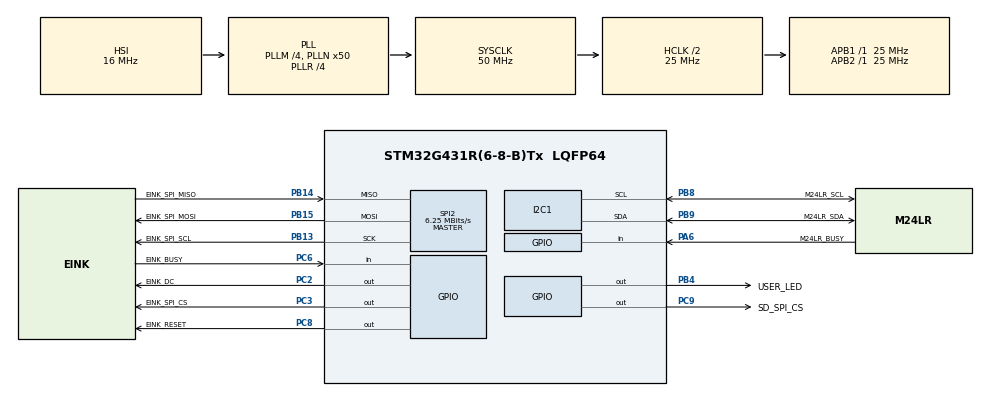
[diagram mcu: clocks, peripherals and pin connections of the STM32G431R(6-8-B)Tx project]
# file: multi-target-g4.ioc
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I2C1.Speed=50
I2C1.Timing=0x0080EBFC
Mcu.Family=STM32G4
Mcu.Name=STM32G431R(6-8-B)Tx
Mcu.Package=LQFP64
NVIC.PriorityGroup=NVIC_PRIORITYGROUP_4
PA13.GPIO_Label=T_SWDIO
PA13.Signal=SYS_JTMS-SWDIO
PA14.GPIO_Label=T_SWCLK
PA14.Signal=SYS_JTCK-SWCLK
PA6.GPIO_Label=M24LR_BUSY
PA6.Signal=GPIO_Input
PB13.GPIO_Label=EINK_SPI_SCL
PB13.Mode=Full_Duplex_Master
PB13.Signal=SPI2_SCK
PB14.GPIO_Label=EINK_SPI_MISO
PB14.Mode=Full_Duplex_Master
PB14.Signal=SPI2_MISO
PB15.GPIO_Label=EINK_SPI_MOSI
PB15.Mode=Full_Duplex_Master
PB15.Signal=SPI2_MOSI
PB3.GPIO_Label=T_SWO
PB3.Signal=SYS_JTDO-SWO
PB4.GPIO_Label=USER_LED
PB4.Signal=GPIO_Output
PB8-BOOT0.GPIO_Label=M24LR_SCL
PB8-BOOT0.Mode=I2C
PB8-BOOT0.Signal=I2C1_SCL
PB9.GPIO_Label=M24LR_SDA
PB9.Mode=I2C
PB9.Signal=I2C1_SDA
PC14-OSC32_IN.GPIO_Label=RCC_OSC32_OUT
PC14-OSC32_IN.Signal=RCC_OSC32_IN
PC15-OSC32_OUT.GPIO_Label=RCC_OSC32_OUT
PC15-OSC32_OUT.Signal=RCC_OSC32_OUT
PC2.GPIO_Label=EINK_DC
PC2.Signal=GPIO_Output
PC3.GPIO_Label=EINK_SPI_CS
PC3.Signal=GPIO_Output
PC6.GPIO_Label=EINK_BUSY
PC6.Signal=GPIO_Input
PC8.GPIO_Label=EINK_RESET
PC8.Signal=GPIO_Output
PC9.GPIO_Label=SD_SPI_CS
PC9.Signal=GPIO_Output
PF0-OSC_IN.GPIO_Label=RCC_OSC_IN
PF0-OSC_IN.Signal=RCC_OSC_IN
PF1-OSC_OUT.GPIO_Label=RCC_OSC_OUT
PF1-OSC_OUT.Signal=RCC_OSC_OUT
ProjectManager.HeapSize=0x200
ProjectManager.StackSize=0x400
ProjectManager.TargetToolchain=STM32CubeIDE
RCC.ADC12Freq_Value=50000000
RCC.AHBCLKDivider=RCC_SYSCLK_DIV2
RCC.AHBFreq_Value=25000000
RCC.APB1Freq_Value=25000000
RCC.APB1TimFreq_Value=25000000
RCC.APB2Freq_Value=25000000
RCC.APB2TimFreq_Value=25000000
RCC.CortexFreq_Value=25000000
RCC.EXTERNAL_CLOCK_VALUE=12288000
RCC.HCLKFreq_Value=25000000
RCC.HSE_VALUE=24000000
RCC.HSI48_VALUE=48000000
RCC.HSI_VALUE=16000000
RCC.LSE_VALUE=32768
RCC.PLLM=RCC_PLLM_DIV4
RCC.PLLN=50
RCC.PLLR=RCC_PLLR_DIV4
RCC.RTCClockSelection=RCC_RTCCLKSOURCE_LSE
RCC.SYSCLKFreq_VALUE=50000000
RCC.SYSCLKSource=RCC_SYSCLKSOURCE_PLLCLK
RCC.USBFreq_Value=100000000
RCC.VCOOutputFreq_Value=200000000
SPI2.BaudRatePrescaler=SPI_BAUDRATEPRESCALER_4
SPI2.CalculateBaudRate=6.25 MBits/s
SPI2.DataSize=SPI_DATASIZE_8BIT
SPI2.Direction=SPI_DIRECTION_2LINES
SPI2.Mode=SPI_MODE_MASTER
SPI2.VirtualType=VM_MASTER
VP_SYS_VS_DBSignals.Mode=DisableDeadBatterySignals
board=NUCLEO-G431RB

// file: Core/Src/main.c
/* USER CODE BEGIN Header */
/**
  ******************************************************************************
  * @file           : main.c
  * @brief          : Main program body
  ******************************************************************************
  * @attention
  *
  * Copyright (c) 2024 STMicroelectronics.
  * All rights reserved.
  *
  * This software is licensed under terms that can be found in the LICENSE file
  * in the root directory of this software component.
  * If no LICENSE file comes with this software, it is provided AS-IS.
  *
  ******************************************************************************
  */
/* USER CODE END Header */
#include "main.h"
#include "i2c.h"
#include "spi.h"
#include "gpio.h"

/* USER CODE BEGIN Includes */
#include "app.h"
/* USER CODE END Includes */

void SystemClock_Config(void);

int main(void)
{

  /* MCU Configuration--------------------------------------------------------*/

  /* Reset of all peripherals, Initializes the Flash interface and the Systick. */
  HAL_Init();

  /* Configure the system clock */
  SystemClock_Config();

  /* Initialize all configured peripherals */
  MX_GPIO_Init();
  MX_SPI2_Init();
  MX_I2C1_Init();
  /* USER CODE BEGIN 2 */
  card_main();
  /* USER CODE END 2 */

  /* Infinite loop */
  while (1)
  {

  }
}

void SystemClock_Config(void)
{
  RCC_OscInitTypeDef RCC_OscInitStruct = {0};
  RCC_ClkInitTypeDef RCC_ClkInitStruct = {0};

  /** Configure the main internal regulator output voltage
  */
  HAL_PWREx_ControlVoltageScaling(PWR_REGULATOR_VOLTAGE_SCALE1);

  /** Initializes the RCC Oscillators according to the specified parameters
  * in the RCC_OscInitTypeDef structure.
  */
  RCC_OscInitStruct.OscillatorType = RCC_OSCILLATORTYPE_HSI;
  RCC_OscInitStruct.HSIState = RCC_HSI_ON;
  RCC_OscInitStruct.HSICalibrationValue = RCC_HSICALIBRATION_DEFAULT;
  RCC_OscInitStruct.PLL.PLLState = RCC_PLL_ON;
  RCC_OscInitStruct.PLL.PLLSource = RCC_PLLSOURCE_HSI;
  RCC_OscInitStruct.PLL.PLLM = RCC_PLLM_DIV4;
  RCC_OscInitStruct.PLL.PLLN = 50;
  RCC_OscInitStruct.PLL.PLLP = RCC_PLLP_DIV2;
  RCC_OscInitStruct.PLL.PLLQ = RCC_PLLQ_DIV2;
  RCC_OscInitStruct.PLL.PLLR = RCC_PLLR_DIV4;
  if (HAL_RCC_OscConfig(&RCC_OscInitStruct) != HAL_OK)
  {
    Error_Handler();
  }

  /** Initializes the CPU, AHB and APB buses clocks
  */
  RCC_ClkInitStruct.ClockType = RCC_CLOCKTYPE_HCLK|RCC_CLOCKTYPE_SYSCLK
                              |RCC_CLOCKTYPE_PCLK1|RCC_CLOCKTYPE_PCLK2;
  RCC_ClkInitStruct.SYSCLKSource = RCC_SYSCLKSOURCE_PLLCLK;
  RCC_ClkInitStruct.AHBCLKDivider = RCC_SYSCLK_DIV2;
  RCC_ClkInitStruct.APB1CLKDivider = RCC_HCLK_DIV1;
  RCC_ClkInitStruct.APB2CLKDivider = RCC_HCLK_DIV1;

  if (HAL_RCC_ClockConfig(&RCC_ClkInitStruct, FLASH_LATENCY_0) != HAL_OK)
  {
    Error_Handler();
  }
}

void Error_Handler(void)
{
  __disable_irq();
  while (1)
  {
  }
}
